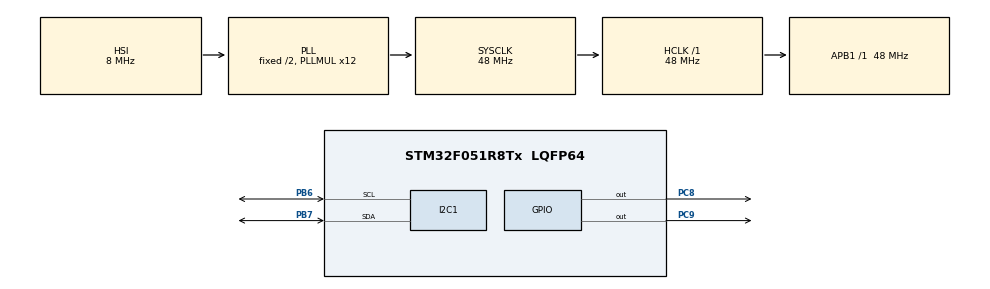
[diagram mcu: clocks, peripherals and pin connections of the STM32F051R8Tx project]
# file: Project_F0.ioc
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I2C1.Analog_Filter=I2C_ANALOGFILTER_DISABLED
I2C1.OwnAddress=0x1
I2C1.Timing=0x00101D2D
Mcu.Family=STM32F0
Mcu.Name=STM32F051R8Tx
Mcu.Package=LQFP64
PB6.GPIO_FM6=__NULL
PB6.GPIO_Mode=GPIO_MODE_AF_OD
PB6.GPIO_PuPdOD=GPIO_PULLUP
PB6.GPIO_Speed=GPIO_SPEED_HIGH
PB6.Mode=I2C
PB6.Signal=I2C1_SCL
PB7.GPIO_FM7=__NULL
PB7.GPIO_Mode=GPIO_MODE_AF_OD
PB7.GPIO_PuPdOD=GPIO_PULLUP
PB7.GPIO_Speed=GPIO_SPEED_HIGH
PB7.Mode=I2C
PB7.Signal=I2C1_SDA
PC8.GPIO_ModeDefaultOutputPP=GPIO_MODE_OUTPUT_PP
PC8.GPIO_PuPd=GPIO_NOPULL
PC8.GPIO_Speed=GPIO_SPEED_HIGH
PC8.Signal=GPIO_Output
PC9.GPIO_ModeDefaultOutputPP=GPIO_MODE_OUTPUT_PP
PC9.GPIO_PuPd=GPIO_NOPULL
PC9.GPIO_Speed=GPIO_SPEED_HIGH
PC9.Signal=GPIO_Output
ProjectManager.TargetToolchain=EWARM
RCC.AHBFreq_Value=48000000
RCC.APB1Freq_Value=48000000
RCC.APB1TimFreq_Value=48000000
RCC.HCLKFreq_Value=48000000
RCC.PLLMUL=RCC_PLL_MUL12
RCC.SYSCLKFreq_VALUE=48000000
RCC.SYSCLKSource=RCC_SYSCLKSOURCE_PLLCLK

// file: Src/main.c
/**
  ******************************************************************************
  * File Name          : main.c
  * Date               : 10/04/2015 19:37:43
  * Description        : Main program body
  ******************************************************************************
  *
  * COPYRIGHT(c) 2015 STMicroelectronics
  *
  * Redistribution and use in source and binary forms, with or without modification,
  * are permitted provided that the following conditions are met:
  *   1. Redistributions of source code must retain the above copyright notice,
  *      this list of conditions and the following disclaimer.
  *   2. Redistributions in binary form must reproduce the above copyright notice,
  *      this list of conditions and the following disclaimer in the documentation
  *      and/or other materials provided with the distribution.
  *   3. Neither the name of STMicroelectronics nor the names of its contributors
  *      may be used to endorse or promote products derived from this software
  *      without specific prior written permission.
  *
  * THIS SOFTWARE IS PROVIDED BY THE COPYRIGHT HOLDERS AND CONTRIBUTORS "AS IS"
  * AND ANY EXPRESS OR IMPLIED WARRANTIES, INCLUDING, BUT NOT LIMITED TO, THE
  * IMPLIED WARRANTIES OF MERCHANTABILITY AND FITNESS FOR A PARTICULAR PURPOSE ARE
  * DISCLAIMED. IN NO EVENT SHALL THE COPYRIGHT HOLDER OR CONTRIBUTORS BE LIABLE
  * FOR ANY DIRECT, INDIRECT, INCIDENTAL, SPECIAL, EXEMPLARY, OR CONSEQUENTIAL
  * DAMAGES (INCLUDING, BUT NOT LIMITED TO, PROCUREMENT OF SUBSTITUTE GOODS OR
  * SERVICES; LOSS OF USE, DATA, OR PROFITS; OR BUSINESS INTERRUPTION) HOWEVER
  * CAUSED AND ON ANY THEORY OF LIABILITY, WHETHER IN CONTRACT, STRICT LIABILITY,
  * OR TORT (INCLUDING NEGLIGENCE OR OTHERWISE) ARISING IN ANY WAY OUT OF THE USE
  * OF THIS SOFTWARE, EVEN IF ADVISED OF THE POSSIBILITY OF SUCH DAMAGE.
  *
  ******************************************************************************
  */

#include "stm32f0xx_hal.h"

I2C_HandleTypeDef hi2c1;

void SystemClock_Config(void);
static void MX_GPIO_Init(void);
static void MX_I2C1_Init(void);

/* USER CODE BEGIN PFP */
uint8_t rxbuffer = 0x0;
/* USER CODE END PFP */

int main(void)
{

  /* MCU Configuration----------------------------------------------------------*/

  /* Reset of all peripherals, Initializes the Flash interface and the Systick. */
  HAL_Init();

  /* Configure the system clock */
  SystemClock_Config();

  /* Initialize all configured peripherals */
  MX_GPIO_Init();
  MX_I2C1_Init();

  /* Infinite loop */
  /* USER CODE BEGIN WHILE */
  while (1)
  {

    HAL_I2C_Slave_Receive(&hi2c1, &rxbuffer, I2C_MEMADD_SIZE_8BIT, 1000);
    if (rxbuffer == 0x1)
    {
      HAL_GPIO_WritePin(GPIOC, GPIO_PIN_8,GPIO_PIN_SET);
      HAL_GPIO_WritePin(GPIOC, GPIO_PIN_9,GPIO_PIN_SET);
    }
    else if (rxbuffer == 0x2)
    {
      HAL_GPIO_WritePin(GPIOC, GPIO_PIN_8,GPIO_PIN_RESET);
      HAL_GPIO_WritePin(GPIOC, GPIO_PIN_9,GPIO_PIN_RESET);
    }
    rxbuffer = 0x0;

  /* USER CODE END WHILE */

  }

}

/** System Clock Configuration
*/
void SystemClock_Config(void)
{

  RCC_OscInitTypeDef RCC_OscInitStruct;
  RCC_ClkInitTypeDef RCC_ClkInitStruct;
  RCC_PeriphCLKInitTypeDef PeriphClkInit;

  RCC_OscInitStruct.OscillatorType = RCC_OSCILLATORTYPE_HSI;
  RCC_OscInitStruct.HSIState = RCC_HSI_ON;
  RCC_OscInitStruct.HSICalibrationValue = 16;
  RCC_OscInitStruct.PLL.PLLState = RCC_PLL_ON;
  RCC_OscInitStruct.PLL.PLLSource = RCC_PLLSOURCE_HSI;
  RCC_OscInitStruct.PLL.PLLMUL = RCC_PLL_MUL12;
  RCC_OscInitStruct.PLL.PREDIV = RCC_PREDIV_DIV1;
  HAL_RCC_OscConfig(&RCC_OscInitStruct);

  RCC_ClkInitStruct.ClockType = RCC_CLOCKTYPE_SYSCLK;
  RCC_ClkInitStruct.SYSCLKSource = RCC_SYSCLKSOURCE_PLLCLK;
  RCC_ClkInitStruct.AHBCLKDivider = RCC_SYSCLK_DIV1;
  RCC_ClkInitStruct.APB1CLKDivider = RCC_HCLK_DIV1;
  HAL_RCC_ClockConfig(&RCC_ClkInitStruct, FLASH_LATENCY_1);

  PeriphClkInit.PeriphClockSelection = RCC_PERIPHCLK_I2C1;
  PeriphClkInit.I2c1ClockSelection = RCC_I2C1CLKSOURCE_HSI;
  HAL_RCCEx_PeriphCLKConfig(&PeriphClkInit);

  __SYSCFG_CLK_ENABLE();

}

/* I2C1 init function */
void MX_I2C1_Init(void)
{

  hi2c1.Instance = I2C1;
  hi2c1.Init.Timing = 0x00101D2D;
  hi2c1.Init.OwnAddress1 = 2;
  hi2c1.Init.AddressingMode = I2C_ADDRESSINGMODE_7BIT;
  hi2c1.Init.DualAddressMode = I2C_DUALADDRESS_DISABLED;
  hi2c1.Init.OwnAddress2 = 0;
  hi2c1.Init.OwnAddress2Masks = I2C_OA2_NOMASK;
  hi2c1.Init.GeneralCallMode = I2C_GENERALCALL_DISABLED;
  hi2c1.Init.NoStretchMode = I2C_NOSTRETCH_DISABLED;
  HAL_I2C_Init(&hi2c1);

    /**Configure Analogue filter
    */
  HAL_I2CEx_AnalogFilter_Config(&hi2c1, I2C_ANALOGFILTER_DISABLED);

}

/** Configure pins as
        * Analog
        * Input
        * Output
        * EVENT_OUT
        * EXTI
*/
void MX_GPIO_Init(void)
{

  GPIO_InitTypeDef GPIO_InitStruct;

  /* GPIO Ports Clock Enable */
  __GPIOC_CLK_ENABLE();
  __GPIOB_CLK_ENABLE();

  /*Configure GPIO pins : PC8 PC9 */
  GPIO_InitStruct.Pin = GPIO_PIN_8|GPIO_PIN_9;
  GPIO_InitStruct.Mode = GPIO_MODE_OUTPUT_PP;
  GPIO_InitStruct.Pull = GPIO_NOPULL;
  GPIO_InitStruct.Speed = GPIO_SPEED_HIGH;
  HAL_GPIO_Init(GPIOC, &GPIO_InitStruct);

}

/************************ (C) COPYRIGHT STMicroelectronics *****END OF FILE****/
